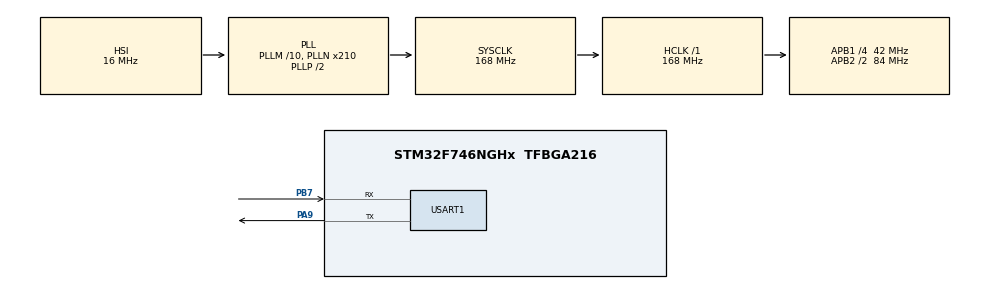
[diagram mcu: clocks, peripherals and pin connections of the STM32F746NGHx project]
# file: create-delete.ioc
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FREERTOS.Tasks01=task1,0,128,StartTask01,Default,NULL,Dynamic,NULL,NULL
Mcu.Family=STM32F7
Mcu.Name=STM32F746NGHx
Mcu.Package=TFBGA216
NVIC.PriorityGroup=NVIC_PRIORITYGROUP_4
NVIC.TIM6_DAC_IRQn=true\:0\:0\:false\:false\:true\:false\:false\:true
NVIC.TimeBase=TIM6_DAC_IRQn
NVIC.TimeBaseIP=TIM6
PA9.Mode=Asynchronous
PA9.Signal=USART1_TX
PB7.Mode=Asynchronous
PB7.Signal=USART1_RX
ProjectManager.HeapSize=0x200
ProjectManager.StackSize=0x400
ProjectManager.TargetToolchain=STM32CubeIDE
RCC.AHBFreq_Value=168000000
RCC.APB1CLKDivider=RCC_HCLK_DIV4
RCC.APB1Freq_Value=42000000
RCC.APB1TimFreq_Value=84000000
RCC.APB2CLKDivider=RCC_HCLK_DIV2
RCC.APB2Freq_Value=84000000
RCC.APB2TimFreq_Value=168000000
RCC.CortexFreq_Value=168000000
RCC.HCLKFreq_Value=168000000
RCC.HSE_VALUE=25000000
RCC.HSI_VALUE=16000000
RCC.LSE_VALUE=32768
RCC.PLLM=10
RCC.PLLN=210
RCC.PLLSourceVirtual=RCC_PLLSOURCE_HSI
RCC.SYSCLKFreq_VALUE=168000000
RCC.SYSCLKSource=RCC_SYSCLKSOURCE_PLLCLK
RCC.USBFreq_Value=168000000
RCC.VCOOutputFreq_Value=336000000
USART1.VirtualMode-Asynchronous=VM_ASYNC
VP_FREERTOS_VS_CMSIS_V1.Mode=CMSIS_V1
VP_SYS_VS_tim6.Mode=TIM6
board=STM32F746G-DISCO

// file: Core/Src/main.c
/* USER CODE BEGIN Header */
/**
  ******************************************************************************
  * @file           : main.c
  * @brief          : Main program body
  ******************************************************************************
  * @attention
  *
  * <h2><center>&copy; Copyright (c) 2021 STMicroelectronics.
  * All rights reserved.</center></h2>
  *
  * This software component is licensed by ST under BSD 3-Clause license,
  * the "License"; You may not use this file except in compliance with the
  * License. You may obtain a copy of the License at:
  *                        opensource.org/licenses/BSD-3-Clause
  *
  ******************************************************************************
  */
/* USER CODE END Header */
#include "main.h"
#include "cmsis_os.h"

/* USER CODE BEGIN Includes */
#include <stdio.h>
/* USER CODE END Includes */

UART_HandleTypeDef huart1;

osThreadId task1Handle;
/* USER CODE BEGIN PV */
osThreadId task2Handle;
/* USER CODE END PV */

void SystemClock_Config(void);
static void MX_GPIO_Init(void);
static void MX_USART1_UART_Init(void);
void StartTask01(void const * argument);

/* USER CODE BEGIN PFP */
void StartTask02(void const * argument);
/* USER CODE END PFP */

/* USER CODE BEGIN 0 */
int _write(int file, char *ptr, int len)
{
	HAL_UART_Transmit(&huart1,(uint8_t *)ptr,len,10);
	return len;
}
/* USER CODE END 0 */

int main(void)
{

  /* MCU Configuration--------------------------------------------------------*/

  /* Reset of all peripherals, Initializes the Flash interface and the Systick. */
  HAL_Init();

  /* Configure the system clock */
  SystemClock_Config();

  /* Initialize all configured peripherals */
  MX_GPIO_Init();
  MX_USART1_UART_Init();

  /* Create the thread(s) */
  /* definition and creation of task1 */
  osThreadDef(task1, StartTask01, osPriorityNormal, 0, 128);
  task1Handle = osThreadCreate(osThread(task1), NULL);

  /* Start scheduler */
  osKernelStart();

  /* We should never get here as control is now taken by the scheduler */
  /* Infinite loop */
  while (1)
  {

  }
}

void SystemClock_Config(void)
{
  RCC_OscInitTypeDef RCC_OscInitStruct = {0};
  RCC_ClkInitTypeDef RCC_ClkInitStruct = {0};
  RCC_PeriphCLKInitTypeDef PeriphClkInitStruct = {0};

  /** Configure the main internal regulator output voltage
  */
  __HAL_RCC_PWR_CLK_ENABLE();
  __HAL_PWR_VOLTAGESCALING_CONFIG(PWR_REGULATOR_VOLTAGE_SCALE2);
  /** Initializes the RCC Oscillators according to the specified parameters
  * in the RCC_OscInitTypeDef structure.
  */
  RCC_OscInitStruct.OscillatorType = RCC_OSCILLATORTYPE_HSI;
  RCC_OscInitStruct.HSIState = RCC_HSI_ON;
  RCC_OscInitStruct.HSICalibrationValue = RCC_HSICALIBRATION_DEFAULT;
  RCC_OscInitStruct.PLL.PLLState = RCC_PLL_ON;
  RCC_OscInitStruct.PLL.PLLSource = RCC_PLLSOURCE_HSI;
  RCC_OscInitStruct.PLL.PLLM = 10;
  RCC_OscInitStruct.PLL.PLLN = 210;
  RCC_OscInitStruct.PLL.PLLP = RCC_PLLP_DIV2;
  RCC_OscInitStruct.PLL.PLLQ = 2;
  if (HAL_RCC_OscConfig(&RCC_OscInitStruct) != HAL_OK)
  {
    Error_Handler();
  }
  /** Initializes the CPU, AHB and APB buses clocks
  */
  RCC_ClkInitStruct.ClockType = RCC_CLOCKTYPE_HCLK|RCC_CLOCKTYPE_SYSCLK
                              |RCC_CLOCKTYPE_PCLK1|RCC_CLOCKTYPE_PCLK2;
  RCC_ClkInitStruct.SYSCLKSource = RCC_SYSCLKSOURCE_PLLCLK;
  RCC_ClkInitStruct.AHBCLKDivider = RCC_SYSCLK_DIV1;
  RCC_ClkInitStruct.APB1CLKDivider = RCC_HCLK_DIV4;
  RCC_ClkInitStruct.APB2CLKDivider = RCC_HCLK_DIV2;

  if (HAL_RCC_ClockConfig(&RCC_ClkInitStruct, FLASH_LATENCY_5) != HAL_OK)
  {
    Error_Handler();
  }
  PeriphClkInitStruct.PeriphClockSelection = RCC_PERIPHCLK_USART1;
  PeriphClkInitStruct.Usart1ClockSelection = RCC_USART1CLKSOURCE_PCLK2;
  if (HAL_RCCEx_PeriphCLKConfig(&PeriphClkInitStruct) != HAL_OK)
  {
    Error_Handler();
  }
}

static void MX_USART1_UART_Init(void)
{

  huart1.Instance = USART1;
  huart1.Init.BaudRate = 115200;
  huart1.Init.WordLength = UART_WORDLENGTH_8B;
  huart1.Init.StopBits = UART_STOPBITS_1;
  huart1.Init.Parity = UART_PARITY_NONE;
  huart1.Init.Mode = UART_MODE_TX_RX;
  huart1.Init.HwFlowCtl = UART_HWCONTROL_NONE;
  huart1.Init.OverSampling = UART_OVERSAMPLING_16;
  huart1.Init.OneBitSampling = UART_ONE_BIT_SAMPLE_DISABLE;
  huart1.AdvancedInit.AdvFeatureInit = UART_ADVFEATURE_NO_INIT;
  if (HAL_UART_Init(&huart1) != HAL_OK)
  {
    Error_Handler();
  }

}

static void MX_GPIO_Init(void)
{

  /* GPIO Ports Clock Enable */
  __HAL_RCC_GPIOB_CLK_ENABLE();
  __HAL_RCC_GPIOA_CLK_ENABLE();

}

/* USER CODE BEGIN 4 */
void StartTask02(void const * argument)
{
  /* USER CODE BEGIN 5 */
  /* Infinite loop */
  for(;;)
  {
	  printf("Deleting task2\r\n");
	  osThreadTerminate(task2Handle);
	  osDelay(1000);
  }
  /* USER CODE END 5 */
}
/* USER CODE END 4 */

void StartTask01(void const * argument)
{
  /* USER CODE BEGIN 5 */
  /* Infinite loop */
  for(;;)
  {
	  printf("Creating task 2\r\n");
	  osThreadDef(task2, StartTask02, osPriorityNormal, 0, 128);
	  task2Handle = osThreadCreate(osThread(task2), NULL);
	  osDelay(1000);
  }
  /* USER CODE END 5 */
}

 /**
  * @brief  Period elapsed callback in non blocking mode
  * @note   This function is called  when TIM6 interrupt took place, inside
  * HAL_TIM_IRQHandler(). It makes a direct call to HAL_IncTick() to increment
  * a global variable "uwTick" used as application time base.
  * @param  htim : TIM handle
  * @retval None
  */
void HAL_TIM_PeriodElapsedCallback(TIM_HandleTypeDef *htim)
{
  if (htim->Instance == TIM6) {
    HAL_IncTick();
  }
}

void Error_Handler(void)
{
  __disable_irq();
  while (1)
  {
  }
}

/************************ (C) COPYRIGHT STMicroelectronics *****END OF FILE****/
